VERSION ""

NS_ :

BS_:

BU_:

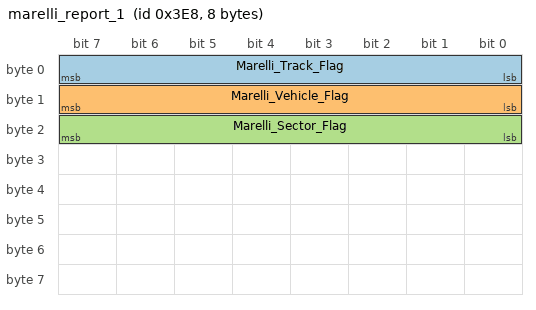
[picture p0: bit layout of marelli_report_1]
BO_ 1000 marelli_report_1: 8 Vector__XXX
 SG_ Marelli_Track_Flag : 0|8@1+ (1,0) [0|0] "" Vector__XXX
 SG_ Marelli_Vehicle_Flag : 8|8@1+ (1,0) [0|0] "" Vector__XXX
 SG_ Marelli_Sector_Flag : 16|8@1+ (1,0) [0|0] "" Vector__XXX

BO_ 1001 marelli_report_2: 8 Vector__XXX
 SG_ lte_sync_ok : 0|1@1+ (1,0) [0|0] "" Vector__XXX
 SG_ lte_modem_lte_rssi : 8|8@1- (1,0) [0|0] "dBm" Vector__XXX

BO_ 1002 marelli_report_3: 8 Vector__XXX
 SG_ GPS_Lat : 0|32@1- (1e-07,0) [0|0] "°" Vector__XXX
 SG_ GPS_Lon : 32|32@1- (1e-07,0) [0|0] "°" Vector__XXX

CM_ BO_ 1000 "Marelli_TX_Report_1";
CM_ SG_ 1000 Marelli_Track_Flag "last TRACK flag received id";
CM_ SG_ 1000 Marelli_Vehicle_Flag "last CAR flag received id";
CM_ SG_ 1000 Marelli_Sector_Flag "last SECTOR flag received id";
CM_ BO_ 1001 "Marelli_TX_Report_2";
CM_ BO_ 1002 "Marelli_TX_Report_3";
CM_ SG_ 1002 GPS_Lat "Latitude";
CM_ SG_ 1002 GPS_Lon "Longitude";
BA_DEF_ BO_  "GenMsgCycleTime" INT 1 1000;
BA_DEF_DEF_  "GenMsgCycleTime" 100;
BA_ "GenMsgCycleTime" BO_ 1000 10;
BA_ "GenMsgCycleTime" BO_ 1001 10;
